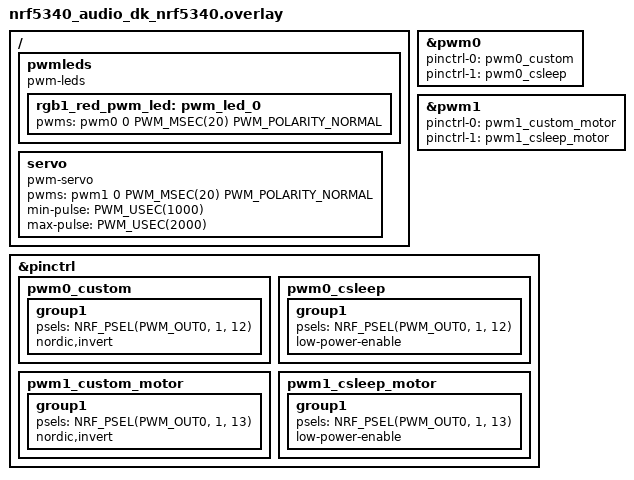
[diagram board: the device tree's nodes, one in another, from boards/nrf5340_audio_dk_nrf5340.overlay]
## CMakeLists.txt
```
#
# Copyright (c) 2024 Nordic Semiconductor
#
# SPDX-License-Identifier: LicenseRef-Nordic-5-Clause
#

cmake_minimum_required(VERSION 3.20.0)
find_package(Zephyr REQUIRED HINTS $ENV{ZEPHYR_BASE})
project(4.2)

target_sources(app PRIVATE src/main.c)
```

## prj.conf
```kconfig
#
# Copyright (c) 2024 Nordic Semiconductor
#
# SPDX-License-Identifier: LicenseRef-Nordic-5-Clause
#

#Logging configurations
CONFIG_LOG=y
CONFIG_PWM_LOG_LEVEL_DBG=y
CONFIG_LOG_PRINTK=y
CONFIG_LOG_MODE_IMMEDIATE=y
CONFIG_STDOUT_CONSOLE=y
CONFIG_PRINTK=y

# PWM and LED configurations
CONFIG_PWM=y
CONFIG_LED=y
CONFIG_LED_PWM=y

# DK Buttons and LEDs library
CONFIG_DK_LIBRARY=y

# NFC pins disable
CONFIG_NFCT_PINS_AS_GPIOS=y
```

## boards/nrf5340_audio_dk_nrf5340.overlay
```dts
/* STEP 1.2 -  Add a pwm_led instance and change the polarity */
/{
    pwmleds {
		compatible = "pwm-leds";
		rgb1_red_pwm_led: pwm_led_0 {
			pwms = <&pwm0 0 PWM_MSEC(20) PWM_POLARITY_NORMAL>;
		};
	};
    servo: servo {
        compatible = "pwm-servo";
        pwms = <&pwm1 0 PWM_MSEC(20) PWM_POLARITY_NORMAL>;
        min-pulse = <PWM_USEC(1000)>;
        max-pulse = <PWM_USEC(2000)>;
    };
};

/* STEP 1.3 - Add your own custom pwm0 instance */
&pwm0 {
    status = "okay";
    pinctrl-0 = <&pwm0_custom>;
    pinctrl-1 = <&pwm0_csleep>;
    pinctrl-names = "default", "sleep";
};

&pwm1 {
    status = "okay";
    pinctrl-0 = <&pwm1_custom_motor>;
    pinctrl-1 = <&pwm1_csleep_motor>;
    pinctrl-names = "default", "sleep";
};

/* STEP 1.4 - Configure which pins your custom pwm0 instance should use */
&pinctrl {
    pwm0_custom: pwm0_custom {
        group1 {
            psels = <NRF_PSEL(PWM_OUT0, 1, 12)>;
            nordic,invert;
        };
    };
    pwm0_csleep: pwm0_csleep {
        group1 {
            psels = <NRF_PSEL(PWM_OUT0, 1, 12)>; 
            low-power-enable;
        };
    };
    pwm1_custom_motor: pwm1_custom_motor {
        group1 {
            psels = <NRF_PSEL(PWM_OUT0, 1, 13)>;
            nordic,invert;
        };
    };
    pwm1_csleep_motor: pwm1_csleep_motor {
        group1 {
            psels = <NRF_PSEL(PWM_OUT0, 1, 13)>;
            low-power-enable;
        };
    };
};


/* STEP 5.2 - Add the servo device */


/* STEP 5.3 - Configure which pins pwm1 should use */
```

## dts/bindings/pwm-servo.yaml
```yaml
# Copyright (c) 2022 Nordic Semiconductor ASA
# SPDX-License-Identifier: Apache-2.0

# STEP 5.1 - Create a device binding for the servo
description: PWM-driven servo motor.
compatible: "pwm-servo"
include: base.yaml
properties:
  pwms:
    required: true
    type: phandle-array
    description: PWM specifier driving the servo motor.
  min-pulse:
    required: true
    type: int
    description: Minimum pulse width (nanoseconds).
  max-pulse:
    required: true
    type: int
    description: Maximum pulse width (nanoseconds).
```

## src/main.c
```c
/*
 * Copyright (c) 2024 Nordic Semiconductor ASA
 *
 * SPDX-License-Identifier: LicenseRef-Nordic-5-Clause
 */
 
#include <zephyr/kernel.h>
#include <zephyr/logging/log.h>
#include <zephyr/device.h>
#include <zephyr/drivers/pwm.h>
#include <dk_buttons_and_leds.h>

LOG_MODULE_REGISTER(Lesson4_Exercise2, LOG_LEVEL_INF);

#define PWM_LED0        DT_ALIAS(pwm_led0)

/* STEP 5.7 - Define the servo motor through its nodelabel */
#define SERVO_MOTOR     DT_NODELABEL(servo) 

static const struct pwm_dt_spec pwm_led0 = PWM_DT_SPEC_GET(PWM_LED0);

/* STEP 5.4 - Retrieve the device structure for the servo motor */
static const struct pwm_dt_spec pwm_servo = PWM_DT_SPEC_GET(DT_NODELABEL(servo));


/* STEP 5.5 - Use DT_PROP() to obtain the minimum and maximum duty cycle */
#define PWM_SERVO_MIN_DUTY_CYCLE  DT_PROP(SERVO_MOTOR, min_pulse)
#define PWM_SERVO_MAX_DUTY_CYCLE  DT_PROP(SERVO_MOTOR, max_pulse)

#define PWM_PERIOD   PWM_MSEC(20)
#define PWM_PERIOD_NS 60000000
/* STEP  2.2 - Define minimum and maximum duty cycle */
#define PWM_MIN_DUTY_CYCLE 20000000
#define PWM_MAX_DUTY_CYCLE 50000000
/* STEP 4.2 - Change the duty cycles for the LED */


/* STEP 2.1 - Create a function to set the angle of the motor */
int set_motor_angle(uint32_t duty_cycle_ns)
{
    int err;
    err = pwm_set_dt(&pwm_led0, PWM_PERIOD_NS, duty_cycle_ns);
    if (err) {
        LOG_ERR("pwm_set_dt_returned %d", err);
    }
    return err;
}

/* STEP 4.3 - Create a function to set the duty cycle of a PWM LED */
int set_led_blink(uint32_t period, uint32_t duty_cycle_ns){
    int err;
    err = pwm_set_dt(&pwm_led0, period, duty_cycle_ns);
        if (err) {
        LOG_ERR("pwm_set_dt_returned %d", err);
    }
    return err;
}

void button_handler(uint32_t button_state, uint32_t has_changed)
{
    int err = 0;
	if (has_changed & button_state)
	{
		switch (has_changed)
		{
            /* STEP 2.4 - Change motor angle when a button is pressed */
            case DK_BTN1_MSK:
                LOG_INF("Button 1 pressed");
                err = set_motor_angle(PWM_SERVO_MIN_DUTY_CYCLE);
                break;
            case DK_BTN2_MSK:
                LOG_INF("Button 2 pressed");
                err = set_motor_angle(PWM_SERVO_MAX_DUTY_CYCLE);
                break;
            /* STEP 5.6 - Update the button handler with the new duty cycle */

            /* STEP 4.4 - Change LED when a button is pressed */
            case DK_BTN3_MSK:
                LOG_INF("Button 3 pressed");
                err = set_led_blink(2*PWM_PERIOD, PWM_MIN_DUTY_CYCLE);
                break;
            case DK_BTN4_MSK:
                LOG_INF("Button 4 pressed");
                err = set_led_blink(4*PWM_PERIOD, PWM_MAX_DUTY_CYCLE);
                break;
		}
        if (err) {
            LOG_ERR("Error: couldn't set duty cycle, err %d", err);
        }
	}
}

int main(void)
{

    int err = 0;
        
    if (dk_buttons_init(button_handler)) {
        LOG_ERR("Failed to initialize the buttons library");
    }

    /* STEP 2.3 - Check if the device is ready and set its initial value */
    if (!pwm_is_ready_dt(&pwm_led0)) {
        LOG_ERR("Error: PWM device %s is not ready", pwm_led0.dev->name);
        return 0;
    }
    err = pwm_set_dt(&pwm_led0, PWM_PERIOD, PWM_MIN_DUTY_CYCLE);
    if (err) {
        LOG_ERR("pwm_set_dt returned %d", err);
        return 0;
    }

    /* STEP 5.7 - Check if the motor device is ready and set its initial value */
    if (!pwm_is_ready_dt(&pwm_servo)) {
        LOG_ERR("Error: PWM device %s is not ready", pwm_servo.dev->name);
        return 0;
    }
    err = pwm_set_dt(&pwm_servo, PWM_PERIOD, PWM_SERVO_MIN_DUTY_CYCLE);
    if (err) {
        LOG_ERR("pwm_set_dt returned %d", err);
        return 0;
    }

    return 0;
}
```
